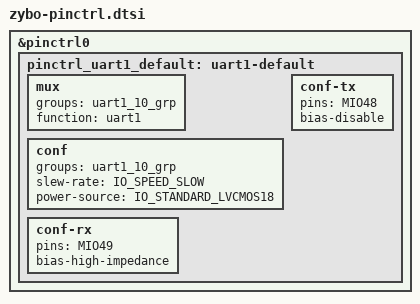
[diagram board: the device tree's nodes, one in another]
/*
 * Copyright (c) 2022 Henrik Brix Andersen <henrik@brixandersen.dk>
 *
 * SPDX-License-Identifier: Apache-2.0
 */

#include <zephyr/dt-bindings/pinctrl/pinctrl-zynq.h>

&pinctrl0 {
	pinctrl_uart1_default: uart1-default {
		mux {
			groups = "uart1_10_grp";
			function = "uart1";
		};

		conf {
			groups = "uart1_10_grp";
			slew-rate = <IO_SPEED_SLOW>;
			power-source = <IO_STANDARD_LVCMOS18>;
		};

		conf-rx {
			pins = "MIO49";
			bias-high-impedance;
		};

		conf-tx {
			pins = "MIO48";
			bias-disable;
		};
	};
};
